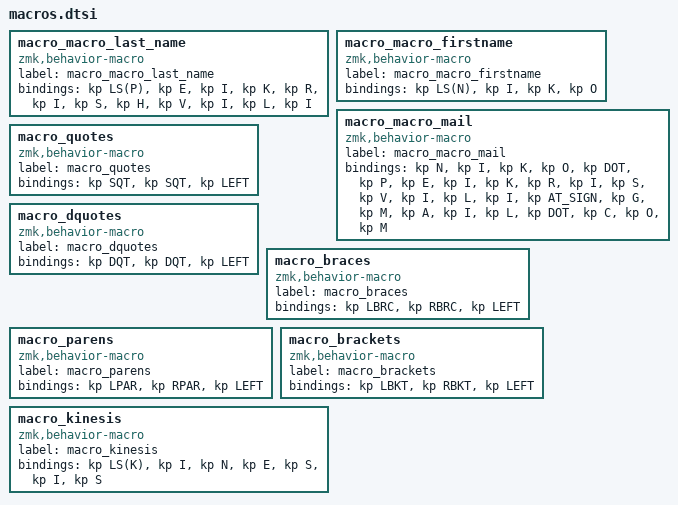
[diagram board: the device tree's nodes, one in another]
macro_macro_last_name: macro_macro_last_name{
compatible = "zmk,behavior-macro";
label = "macro_macro_last_name";
#binding-cells = <0>;
bindings = <&kp LS(P)>, <&kp E>, <&kp I>, <&kp K>, <&kp R>, <&kp I>, <&kp S>, <&kp H>, <&kp V>, <&kp I>, <&kp L>, <&kp I>;
};
macro_macro_firstname: macro_macro_firstname{
compatible = "zmk,behavior-macro";
label = "macro_macro_firstname";
#binding-cells = <0>;
bindings = <&kp LS(N)>, <&kp I>, <&kp K>, <&kp O>;
};
macro_macro_mail: macro_macro_mail{
compatible = "zmk,behavior-macro";
label = "macro_macro_mail";
#binding-cells = <0>;
bindings = <&kp N>, <&kp I>, <&kp K>, <&kp O>, <&kp DOT>, <&kp P>, <&kp E>, <&kp I>, <&kp K>, <&kp R>, <&kp I>, <&kp S>, <&kp V>, <&kp I>, <&kp L>, <&kp I>, <&kp AT_SIGN>, <&kp G>, <&kp M>, <&kp A>, <&kp I>, <&kp L>, <&kp DOT>, <&kp C>, <&kp O>, <&kp M>;
};
macro_quotes: macro_quotes{
compatible = "zmk,behavior-macro";
label = "macro_quotes";
#binding-cells = <0>;
bindings = <&kp SQT>, <&kp SQT>, <&kp LEFT>;
};
macro_dquotes: macro_dquotes{
compatible = "zmk,behavior-macro";
label = "macro_dquotes";
#binding-cells = <0>;
bindings = <&kp DQT>, <&kp DQT>, <&kp LEFT>;
};
macro_braces: macro_braces{
compatible = "zmk,behavior-macro";
label = "macro_braces";
#binding-cells = <0>;
bindings = <&kp LBRC>, <&kp RBRC>, <&kp LEFT>;
};
macro_parens: macro_parens{
compatible = "zmk,behavior-macro";
label = "macro_parens";
#binding-cells = <0>;
bindings = <&kp LPAR>, <&kp RPAR>, <&kp LEFT>;
};
macro_brackets: macro_brackets{
compatible = "zmk,behavior-macro";
label = "macro_brackets";
#binding-cells = <0>;
bindings = <&kp LBKT>, <&kp RBKT>, <&kp LEFT>;
};
macro_kinesis: macro_kinesis{
compatible = "zmk,behavior-macro";
label = "macro_kinesis";
#binding-cells = <0>;
bindings = <&kp LS(K)>, <&kp I>, <&kp N>, <&kp E>, <&kp S>, <&kp I>, <&kp S>;
};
